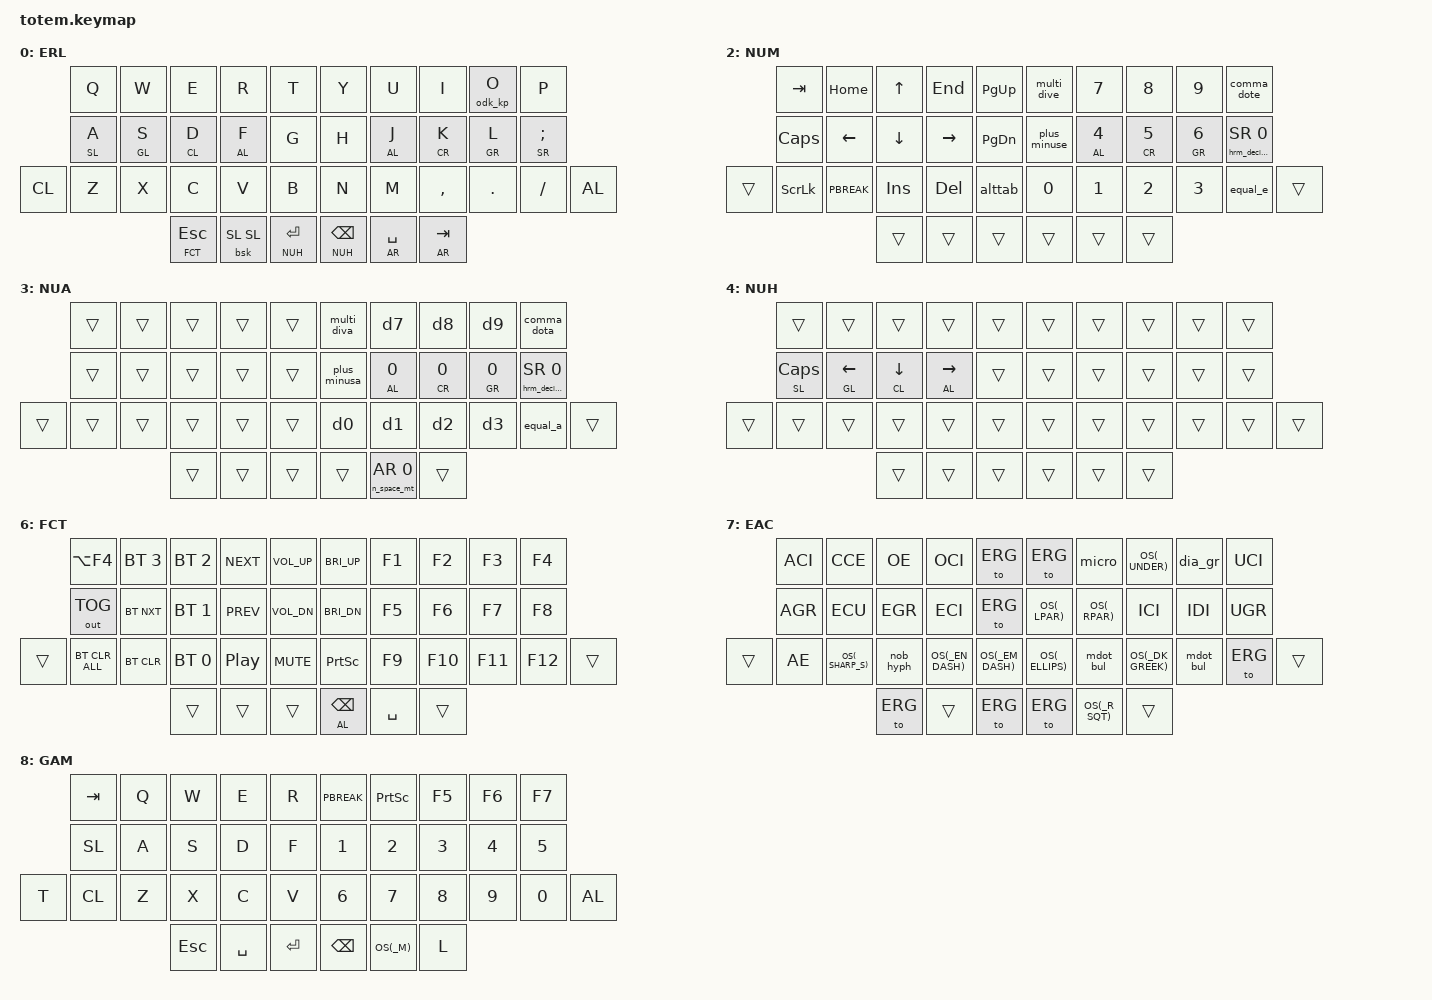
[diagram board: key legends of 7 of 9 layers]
//
//                                                        ▀▀▀▀▀     ▀▀▀▀▀          ▀▀█▀▀
//                                                        ▄▀▀▀▄  ▄  ▄▀▀▀▄  ▄  ▄▀▀▀▄  █  ▄▀▀▀▄
//                                                        █   █  █  █   █  █  █   █  █  █   █
//                                                         ▀▀▀   █   ▀▀▀   █   ▀▀▀   ▀   ▀▀▀
//                                                               █      ▄▄▄█▄▄▄    █   █  
//                                                               ▀      █  █  █     █▄█
//                                                             ▀▀▀▀▀    █  █  █      ▀
//                                                                      ▀  ▀  ▀
//
// ▄▄▄▄▄▄▄▄▄▄▄▄▄▄▄▄▄▄▄▄▄▄▄▄▄▄▄▄▄▄▄▄▄▄▄▄▄▄▄▄▄▄▄▄▄▄▄▄▄▄▄▄▄▄▄▄▄▄▄▄▄▄▄▄▄▄▄▄▄▄▄▄▄▄▄▄▄▄▄▄▄▄▄▄▄▄▄▄▄▄▄▄▄▄▄▄▄▄▄▄▄▄▄▄▄▄▄▄▄▄▄▄▄▄▄▄▄▄▄▄▄▄▄▄▄▄▄▄▄▄▄▄▄▄▄▄▄▄▄▄▄▄▄▄▄▄▄▄▄


#include <dt-bindings/zmk/keys.h>
#include <behaviors.dtsi>
#include <dt-bindings/zmk/bt.h>
#include <dt-bindings/zmk/outputs.h>

// Modifier keys - shortcuts for the layers bindings
#define   GL  LGUI
#define   CL  LCTRL
#define   AL  LALT
#define   SL  LSHFT
#define   GR  RGUI
#define   CR  RCTRL
#define   AR  RALT
#define   SR  RSHFT

// Layers
#define   ERL   0
#define   ERG   1
#define   NUM   2
#define   NUA   3
#define   NUH   4
#define   SYM   5
#define   FCT   6
#define   EAC   7
#define   GAM   8

// Keys
#define   ___       &trans
#define   BACK_EAC  &to ERG
#define   PBREAK    PAUSE_BREAK

#include "layouts/fr-azerty-alt.dtsi"
#include "layouts/fr-azerty-modern.dtsi"
#include "layouts/fr-ergol.dtsi"

#include "behaviors/one-dead-key.dtsi"
#include "behaviors/capsword.dtsi"
#include "behaviors/macros.dtsi"
#include "behaviors/mod-morph.dtsi"
#include "behaviors/hold-tap.dtsi"
#include "behaviors/combos-totem.dtsi"
#include "behaviors/conditional-layers.dtsi"

/ {
  keymap {
    compatible = "zmk,keymap";
    
    // Computer-managed layer - QWERTY-based sent keys, adapted per activated layout on OS
    // Best with Ergo-L because NavNum accessed from here is maped for Ergo-L
    ErgolBase {
      display-name = "ERL";
      bindings = <
//             ╭───────────┬───────────┬───────────┬────────────┬────────────╮ ╭───────────┬─────────────┬─────────────┬────────────┬────────────╮
                 &kp Q       &kp W       &kp E       &kp R        &kp T          &kp Y       &kp U         &kp I         &odk_kp O    &kp P
//             ├───────────┼───────────┼───────────┼────────────┼────────────┤ ├───────────┼─────────────┼─────────────┼────────────┼────────────┤
                 &hrm SL A   &hrm GL S   &hrm CL D   &hrm AL F    &kp G          &kp  H      &hrm AL J     &hrm CR K     &hrm GR L    &hrm SR SEMI
// ╭───────────├───────────┼───────────┼───────────┼────────────┼────────────┤ ├───────────┼─────────────┼─────────────┼────────────┼────────────┤────────────╮
     &kp CL      &kp Z       &kp X       &kp C       &kp V        &kp B          &kp N       &kp M         &kp COMMA     &kp PERIOD   &kp SLASH    &kp AL
// ╰───────────├───────────┴───────────┼───────────┼────────────┼────────────┤ ├───────────┼─────────────┼─────────────┼────────────┴────────────┴────────────╯
                                        &lt FCT ESC  &bsk SL SL   &lt NUH RET   &lt NUH BSPC &mt AR SPACE  &mt AR TAB
//                                     ╰───────────┴────────────┴────────────╯ ╰───────────┴─────────────┴─────────────╯
      >;
    };

    // OS-based sent keys (AZERTY defined), Ergo-L emulated
    ErgolAz {
      display-name = "ERG";
      bindings = <
//             ╭───────────┬───────────┬───────────┬────────────┬────────────╮ ╭───────────┬─────────────┬─────────────┬────────────┬────────────╮
                 &kp OS(_Q)  &kp OS(_C) &kp OS(_O)  &kp OS(_P)    &kp OS(_W)     &kp OS(_J)  &kp OS(_M)    &kp OS(_D)    &eac_exl     &kp OS(_Y)
//             ├───────────┼───────────┼───────────┼────────────┼────────────┤ ├───────────┼─────────────┼─────────────┼────────────┼────────────┤
        &hrm SL OS(_A) &hrm GL OS(_S) &hrm CL OS(_E) &hrm AL OS(_N) &kp OS(_F) &kp OS(_L) &hrm AL OS(_R) &hrm CR OS(_T) &hrm GR OS(_I) &hrm SR OS(_U)
// ╭───────────├───────────┼───────────┼───────────┼────────────┼────────────┤ ├───────────┼─────────────┼─────────────┼────────────┼────────────┤────────────╮
     ___         &kp OS(_Z)  &kp OS(_X)  &min_qst    &kp OS(_V)   &kp OS(_B)     &dot_col    &kp OS(_H)    &kp OS(_G)    &comma_semi  &kp OS(_K)   ___
// ╰───────────├───────────┴───────────┼───────────┼────────────┼────────────┤ ├───────────┼─────────────┼─────────────┼────────────┴────────────┴────────────╯
                                         ___         ___          ___            ___      &n_space_lt SYM 0 ___
//                                     ╰───────────┴────────────┴────────────╯ ╰───────────┴─────────────┴─────────────╯
      >;
    };

    // Ergo-L-based sent keys
    NavNumBase {
      display-name = "NUM";
      bindings = <
//             ╭───────────┬───────────┬───────────┬────────────┬────────────╮ ╭───────────┬─────────────┬─────────────┬────────────┬────────────╮
                 &kp TAB     &kp HOME    &kp UP      &kp END      &kp PG_UP     &multi_dive  &kp N7        &kp N8        &kp N9       &comma_dote
//             ├───────────┼───────────┼───────────┼────────────┼────────────┤ ├───────────┼─────────────┼─────────────┼────────────┼────────────┤
                 &kp CAPS    &kp LEFT    &kp DOWN    &kp RIGHT    &kp PG_DN     &plus_minuse &hrm AL N4    &hrm CR N5    &hrm GR N6 &hrm_decim_e SR 0
// ╭───────────├───────────┼───────────┼───────────┼────────────┼────────────┤ ├───────────┼─────────────┼─────────────┼────────────┼────────────┤────────────╮
     ___         &kp SLCK    &kp PBREAK  &kp INS     &kp DEL      &alttab        &kp N0      &kp N1        &kp N2        &kp N3       &equal_e     ___
// ╰───────────┴───────────┼───────────┼───────────┼────────────┼────────────┤ ├───────────┼─────────────┼─────────────┼────────────┴────────────┴────────────╯
                                         ___         ___          ___            ___         ___           ___
//                                     ╰───────────┴────────────┴────────────╯ ╰───────────┴─────────────┴─────────────╯
      >;
    };

    // OS-based sent keys (AZERTY defined), Ergo-L emulated
    // must be activated with NUM under it (done with conditional_layers)
    NavNumAz {
      display-name = "NUA";
      bindings = <
//             ╭───────────┬───────────┬───────────┬────────────┬────────────╮ ╭───────────┬─────────────┬─────────────┬────────────┬────────────╮
                 ___         ___         ___         ___          ___           &multi_diva  &d7           &d8           &d9          &comma_dota
//             ├───────────┼───────────┼───────────┼────────────┼────────────┤ ├───────────┼─────────────┼─────────────┼────────────┼────────────┤
                 ___         ___         ___         ___          ___           &plus_minusa &hrm_d4 AL 0 &hrm_d5 CR 0 &hrm_d6 GR 0 &hrm_decim_a SR 0
// ╭───────────├───────────┼───────────┼───────────┼────────────┼────────────┤ ├───────────┼─────────────┼─────────────┼────────────┼────────────┤────────────╮
     ___         ___         ___         ___         ___          ___            &d0         &d1           &d2           &d3          &equal_a     ___
// ╰───────────┴───────────┼───────────┼───────────┼────────────┼────────────┤ ├───────────┼─────────────┼─────────────┼────────────┴────────────┴────────────╯
                                         ___         ___          ___            ___      &n_space_mt AR 0 ___
//                                     ╰───────────┴────────────┴────────────╯ ╰───────────┴─────────────┴─────────────╯
      >;
    };

    // OS-based sent keys (AZERTY defined), Ergo-L emulated
    // must be activated with NUM under it (done with conditional_layers)
    NavNumHRM {
      display-name = "NUH";
      bindings = <
//             ╭───────────┬───────────┬───────────┬────────────┬────────────╮ ╭───────────┬─────────────┬─────────────┬────────────┬────────────╮
                 ___         ___         ___         ___          ___            ___         ___           ___           ___          ___
//             ├───────────┼───────────┼───────────┼────────────┼────────────┤ ├───────────┼─────────────┼─────────────┼────────────┼────────────┤
              &hrm SL CAPS &hrm GL LEFT &hrm CL DOWN &hrm AL RIGHT ___           ___         ___           ___           ___          ___
// ╭───────────├───────────┼───────────┼───────────┼────────────┼────────────┤ ├───────────┼─────────────┼─────────────┼────────────┼────────────┤────────────╮
     ___         ___         ___         ___         ___          ___            ___         ___           ___           ___          ___          ___
// ╰───────────┴───────────┼───────────┼───────────┼────────────┼────────────┤ ├───────────┼─────────────┼─────────────┼────────────┴────────────┴────────────╯
                                         ___         ___          ___            ___         ___           ___
//                                     ╰───────────┴────────────┴────────────╯ ╰───────────┴─────────────┴─────────────╯
      >;
    };

    // OS-based sent keys (AZERTY defined), Ergo-L emulated
    // AltGr emulation
    Symbols {
      display-name = "SYM";
      bindings = <
//             ╭───────────┬───────────┬───────────┬────────────┬────────────╮ ╭───────────┬─────────────┬─────────────┬────────────┬────────────╮
                 &circacc    &lessert    &greatert   &dollars     &perct         &arobase   &kp OS(_AMPS)  &starmul      &squotecute  &graveacc
//             ├───────────┼───────────┼───────────┼────────────┼────────────┤ ├───────────┼─────────────┼─────────────┼────────────┼────────────┤
 &hrmlbrace SL 0 &hrm AL OS(_LPAR) &hrm GL OS(_RPAR) &hrmrbrace CL 0 &equaldif &bslashobl &hrmplus CR 0 &hrmhyphen GR 0 &hrmslash AL 0 &hrmdquote SR 0
// ╭───────────├───────────┼───────────┼───────────┼────────────┼────────────┤ ├───────────┼─────────────┼─────────────┼────────────┼────────────┤────────────╮
     ___         &tildes     &lbracketc  &rbracketo  &underscruh &kp OS(_HASH) &kp OS(_PIPE) &kp OS(_EXCL) &semicolced   &coloneach   &questionm   ___
// ╰───────────┴───────────┼───────────┼───────────┼────────────┼────────────┤ ├───────────┼─────────────┼─────────────┼────────────┴────────────┴────────────╯
                                         ___         ___          ___            ___         &nbspac       ___
//                                     ╰───────────┴────────────┴────────────╯ ╰───────────┴─────────────┴─────────────╯
      >;
    };

    Funct {
      display-name = "FCT";
      bindings = <
//             ╭───────────┬───────────┬───────────┬────────────┬────────────╮ ╭───────────┬─────────────┬─────────────┬────────────┬────────────╮
                &kp LA(F4) &bt BT_SEL 3 &bt BT_SEL 2 &kp C_NEXT  &kp C_VOL_UP   &kp C_BRI_UP &kp F1        &kp F2        &kp F3       &kp F4
//             ├───────────┼───────────┼───────────┼────────────┼────────────┤ ├───────────┼─────────────┼─────────────┼────────────┼────────────┤
                &out OUT_TOG &bt BT_NXT &bt BT_SEL 1 &kp C_PREV  &kp C_VOL_DN   &kp C_BRI_DN &kp F5        &kp F6        &kp F7       &kp F8
// ╭───────────├───────────┼───────────┼───────────┼────────────┼────────────┤ ├───────────┼─────────────┼─────────────┼────────────┼────────────┤────────────╮
     ___      &bt BT_CLR_ALL &bt BT_CLR &bt BT_SEL 0 &kp C_PP     &kp C_MUTE     &kp PSCRN   &kp F9        &kp F10       &kp F11      &kp F12      ___
// ╰───────────┴───────────┼───────────┼───────────┼────────────┼────────────┤ ├───────────┼─────────────┼─────────────┼────────────┴────────────┴────────────╯
                                         ___         ___          ___            &mt AL BSPC &kp SPACE     ___
//                                     ╰───────────┴────────────┴────────────╯ ╰───────────┴─────────────┴─────────────╯
      >;
    };

    // AZERTY-based sent keys, Ergo-L emulated
    // One-Dead-Key emulation
    ErgAzAcc {
      display-name = "EAC";
      bindings = <
//             ╭───────────┬───────────┬───────────┬────────────┬────────────╮ ╭───────────┬─────────────┬─────────────┬────────────┬────────────╮
                 &ACI        &CCE        &OE         &OCI         BACK_EAC       BACK_EAC    &micro      &kp OS(_UNDER)  &dia_gr      &UCI
//             ├───────────┼───────────┼───────────┼────────────┼────────────┤ ├───────────┼─────────────┼─────────────┼────────────┼────────────┤
                 &AGR        &ECU        &EGR        &ECI         BACK_EAC    &kp OS(_LPAR) &kp OS(_RPAR)  &ICI          &IDI         &UGR
// ╭───────────├───────────┼───────────┼───────────┼────────────┼────────────┤ ├───────────┼─────────────┼─────────────┼────────────┼────────────┤────────────╮
     ___       &AE &kp OS(_SHARP_S) &nob_hyph &kp OS(_EN_DASH) &kp OS(_EM_DASH) &kp OS(_ELLIPS) &mdot_bul &kp OS(_DK_GREEK) &mdot_bul BACK_EAC     ___
// ╰───────────├───────────┴───────────┼───────────┼────────────┼────────────┤ ├───────────┼─────────────┼─────────────┼────────────┴────────────┴────────────╯
                                         BACK_EAC    ___          BACK_EAC       BACK_EAC   &kp OS(_R_SQT)  ___
//                                     ╰───────────┴────────────┴────────────╯ ╰───────────┴─────────────┴─────────────╯
      >;
    };

    Game {
      display-name = "GAM";
      bindings = <
//             ╭───────────┬───────────┬───────────┬────────────┬────────────╮ ╭───────────┬─────────────┬─────────────┬────────────┬────────────╮
                 &kp TAB     &kp Q       &kp W       &kp E        &kp R          &kp PBREAK  &kp PSCRN    &kp F5        &kp F6       &kp F7
//             ├───────────┼───────────┼───────────┼────────────┼────────────┤ ├───────────┼─────────────┼─────────────┼────────────┼────────────┤
                 &kp SL      &kp A       &kp S       &kp D        &kp F          &kp N1      &kp N2        &kp N3        &kp N4       &kp N5
// ╭───────────├───────────┼───────────┼───────────┼────────────┼────────────┤ ├───────────┼─────────────┼─────────────┼────────────┼────────────┤────────────╮
     &kp T       &kp CL      &kp Z       &kp X       &kp C        &kp V          &kp N6      &kp N7        &kp N8        &kp N9       &kp N0       &kp AL
// ╰───────────┴───────────┼───────────┼───────────┼────────────┼────────────┤ ├───────────┼─────────────┼─────────────┼────────────┴────────────┴────────────╯
                                         &kp ESC     &kp SPACE    &kp RET        &kp BSPC    &kp OS(_M)    &kp L
//                                     ╰───────────┴────────────┴────────────╯ ╰───────────┴─────────────┴─────────────╯
      >;
    };
    
  };
};
